# STM32U545 register map
File version: 1.0
CPU: CM33 r0p1, little endian, MPU, FPU, 4 interrupt priority bits
Registers are 32-bit, read-write, reset 0x0 unless marked. A register's access mark holds for its fields unless they carry their own. Offsets are from the block's base; [hi:lo] are bit positions; {n}, {i} and the like mark numbered series; 'fields as' and 'values as' point back to an identical list.

## OPAMP — Operational amplifiers
Base 0x46005000
Same registers: SEC_OPAMP 0x56005000
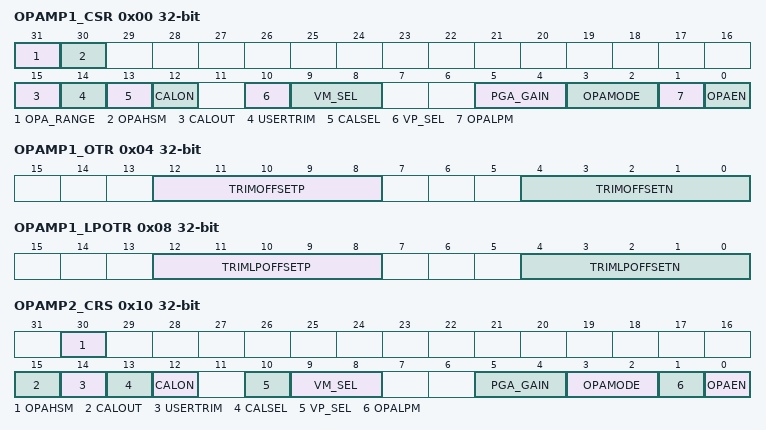
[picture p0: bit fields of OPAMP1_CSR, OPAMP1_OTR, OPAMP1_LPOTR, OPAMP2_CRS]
0x00 OPAMP1_CSR access per field — OPAMP1 control/status register
  [31] OPA_RANGE rw — OPAMP range setting This bit must be set before enabling the OPAMP and this bit affects all OPAMP instances.
  [30] OPAHSM rw — OPAMP high-speed mode This bit is effective for both normal and low-power modes.
  [15] CALOUT ro — OPAMP calibration output During the calibration mode, the offset is trimmed when this signal toggles.
  [14] USERTRIM rw — ‘factory’ or ‘user’ offset trimmed values selection This bit is active for normal and low-power modes.
  [13] CALSEL rw — Calibration selection
  [12] CALON rw — Calibration mode enable
  [10] VP_SEL rw — Non-inverted input selection
  [9:8] VM_SEL rw — Inverting input selection These bits are used only when OPAMODE = 00, 01 or 10. 1x: inverting input not externally connected
  [5:4] PGA_GAIN rw — OPAMP programmable amplifier gain value
  [3:2] OPAMODE rw — OPAMP PGA mode 00 and 01: internal PGA disabled
  [1] OPALPM rw — OPAMP low-power mode The OPAMP must be disabled to change this configuration.
  [0] OPAEN rw — OPAMP enable
0x04 OPAMP1_OTR (reset mask 0xFFFF0000) — OPAMP1 offset trimming register in normal mode
  [12:8] TRIMOFFSETP — Trim for PMOS differential pairs
  [4:0] TRIMOFFSETN — Trim for NMOS differential pairs
0x08 OPAMP1_LPOTR (reset mask 0xFFFF0000) — OPAMP1 offset trimming register in low-power mode
  [12:8] TRIMLPOFFSETP — Low-power mode trim for PMOS differential pairs
  [4:0] TRIMLPOFFSETN — Low-power mode trim for NMOS differential pairs
0x10 OPAMP2_CRS access per field — OPAMP2 control/status register
  [30] OPAHSM rw — OPAMP high-speed mode This bit is effective for both normal and high-speed modes.
  [15] CALOUT ro — OPAMP calibration output During calibration mode, the offset is trimmed when this signal toggles.
  [14] USERTRIM rw — ‘factory’ or ‘user’ offset trimmed values selection This bit is active for normal and low-power modes.
  [13] CALSEL rw — Calibration selection
  [12] CALON rw — Calibration mode enable
  [10] VP_SEL rw — Non inverted input selection
  [9:8] VM_SEL rw — Inverting input selection These bits are used only when OPAMODE = 00, 01 or 10. in PGA mode for filtering) 1x: inverting input not externally connected
  [5:4] PGA_GAIN rw — OPAMP programmable amplifier gain value
  [3:2] OPAMODE rw — OPAMP PGA mode 00 and 01: internal PGA disabled
  [1] OPALPM rw — OPAMP low-power mode The OPAMP must be disabled to change this configuration.
  [0] OPAEN rw — OPAMP enable
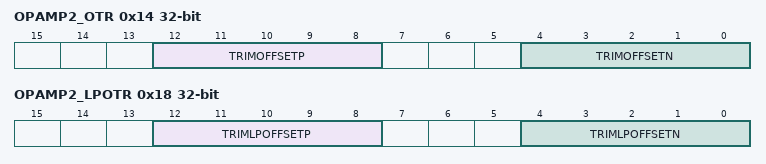
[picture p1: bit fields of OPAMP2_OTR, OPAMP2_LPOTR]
0x14 OPAMP2_OTR (reset mask 0xFFFF0000) — OPAMP2 offset trimming register in normal mode
  fields as OPAMP1_OTR
0x18 OPAMP2_LPOTR (reset mask 0xFFFF0000) — OPAMP2 offset trimming register in low-power mode
  fields as OPAMP1_LPOTR

## PKA — Private key accelerator
Base 0x420C2000
Same registers: SEC_PKA 0x520C2000
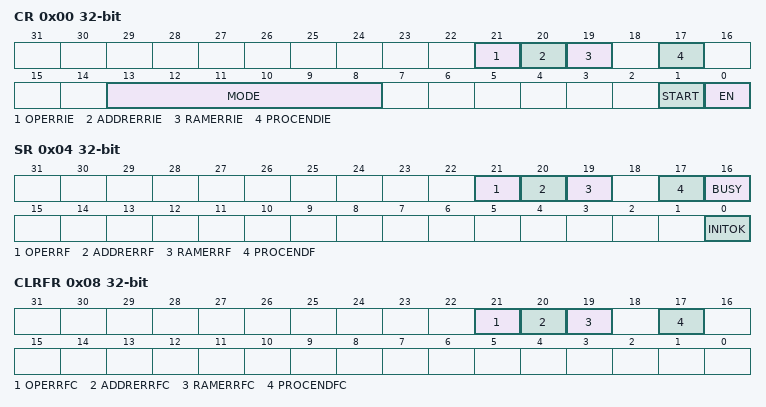
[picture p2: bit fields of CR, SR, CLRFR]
0x00 CR — Control register
  [21] OPERRIE — Operation error interrupt enable
  [20] ADDRERRIE — Address error interrupt enable
  [19] RAMERRIE — RAM error interrupt enable
  [17] PROCENDIE — End of operation interrupt enable
  [13:8] MODE — PKA Operation Mode
  [1] START — Start the operation
  [0] EN — Peripheral Enable
0x04 SR ro — PKA status register
  [21] OPERRF
  [20] ADDRERRF
  [19] RAMERRF
  [17] PROCENDF — PKA End of Operation flag
  [16] BUSY — PKA operation is in progress
  [0] INITOK
0x08 CLRFR wo — PKA clear flag register
  [21] OPERRFC
  [20] ADDRERRFC
  [19] RAMERRFC
  [17] PROCENDFC — Clear PKA End of Operation flag

## RAMCFG
Base 0x40026000
Same registers: SEC_RAMCFG 0x50026000
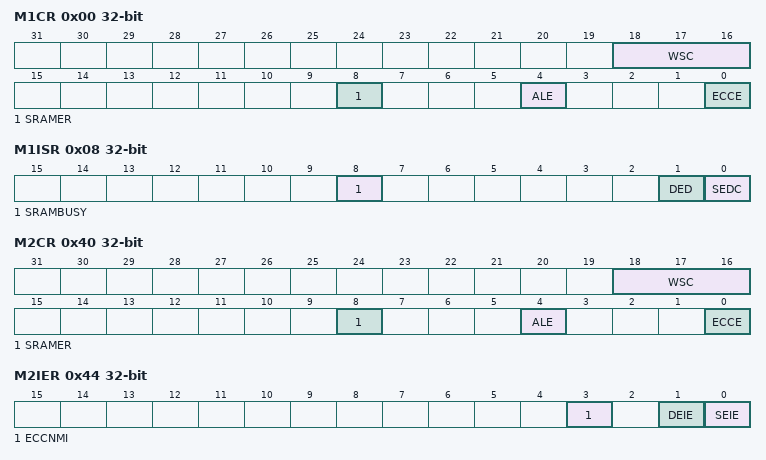
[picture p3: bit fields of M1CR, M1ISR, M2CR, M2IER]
0x00 M1CR — RAMCFG SRAM x control register
  [18:16] WSC, [8] SRAMER, [4] ALE, [0] ECCE
0x08 M1ISR ro — RAMCFG RAMx interrupt status register
  [8] SRAMBUSY, [1] DED, [0] SEDC
0x28 RAM1ERKEYR wo — RAMCFG SRAM x erase key register
  [7:0] ERASEKEY
0x40 M2CR — RAMCFG SRAM x control register
  [18:16] WSC, [8] SRAMER, [4] ALE, [0] ECCE
0x44 M2IER — RAMCFG SRAM x interrupt enable register
  [3] ECCNMI, [1] DEIE, [0] SEIE
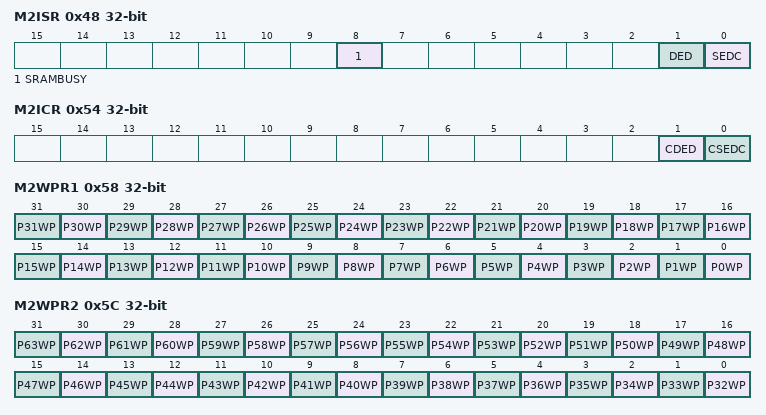
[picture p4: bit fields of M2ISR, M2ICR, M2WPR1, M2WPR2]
0x48 M2ISR ro — RAMCFG RAMx interrupt status register
  [8] SRAMBUSY, [1] DED, [0] SEDC
0x4C M2SEAR ro — RAMCFG RAM x ECC single error address register
  [31:0] ESEA
0x50 M2DEAR ro — RAMCFG RAM x ECC double error address register
  [31:0] EDEA
0x54 M2ICR — RAMCFG RAM x interrupt clear register x
  [1] CDED, [0] CSEDC
0x58 M2WPR1 — RAMCFG SRAM2 write protection register 1
  [n] P{n}WP (n=0..31)
0x5C M2WPR2 — RAMCFG SRAM2 write protection register 2
  [n-32] P{n}WP (n=32..63)
0x64 M2ECCKEYR wo — RAMCFG SRAM x ECC key register
  [7:0] ECCKEY
0x68 M2ERKEYR wo — RAMCFG SRAM x erase key register
  [7:0] ERASEKEY
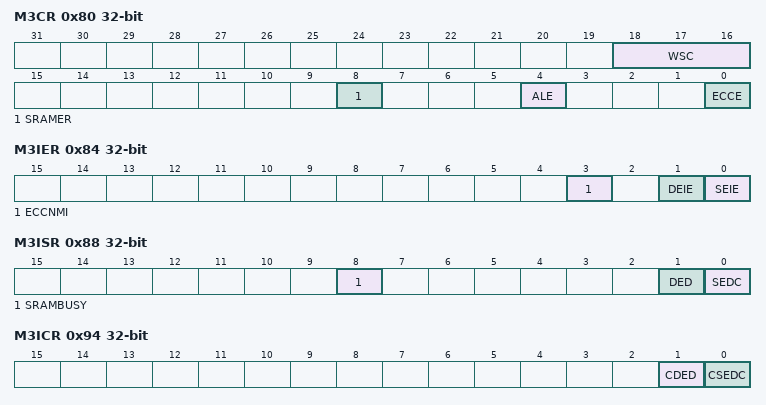
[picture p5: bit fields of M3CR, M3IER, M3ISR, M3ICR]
0x80 M3CR — RAMCFG SRAM x control register
  [18:16] WSC, [8] SRAMER, [4] ALE, [0] ECCE
0x84 M3IER — RAMCFG SRAM x interrupt enable register
  [3] ECCNMI, [1] DEIE, [0] SEIE
0x88 M3ISR ro — RAMCFG RAMx interrupt status register
  [8] SRAMBUSY, [1] DED, [0] SEDC
0x8C M3SEAR ro — RAMCFG RAM x ECC single error address register
  [31:0] ESEA
0x90 M3DEAR ro — RAMCFG RAM x ECC double error address register
  [31:0] EDEA
0x94 M3ICR — RAMCFG RAM x interrupt clear register x
  [1] CDED, [0] CSEDC
0xA4 M3ECCKEYR wo — RAMCFG SRAM x ECC key register
  [7:0] ECCKEY
0xA8 M3ERKEYR wo — RAMCFG SRAM x erase key register
  [7:0] ERASEKEY
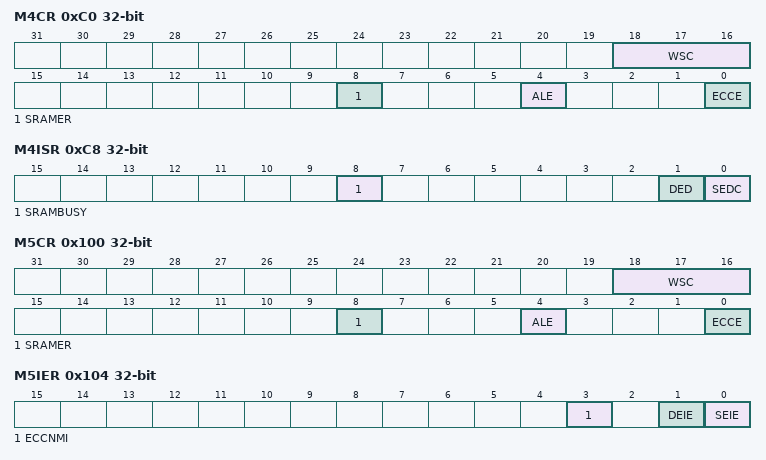
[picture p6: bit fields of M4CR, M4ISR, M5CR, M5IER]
0xC0 M4CR — RAMCFG SRAM x control register
  [18:16] WSC, [8] SRAMER, [4] ALE, [0] ECCE
0xC8 M4ISR ro — RAMCFG RAMx interrupt status register
  [8] SRAMBUSY, [1] DED, [0] SEDC
0xE8 M4ERKEYR wo — RAMCFG SRAM x erase key register
  [7:0] ERASEKEY
0x100 M5CR — RAMCFG SRAM x control register
  [18:16] WSC, [8] SRAMER, [4] ALE, [0] ECCE
0x104 M5IER — RAMCFG SRAM x interrupt enable register
  [3] ECCNMI, [1] DEIE, [0] SEIE
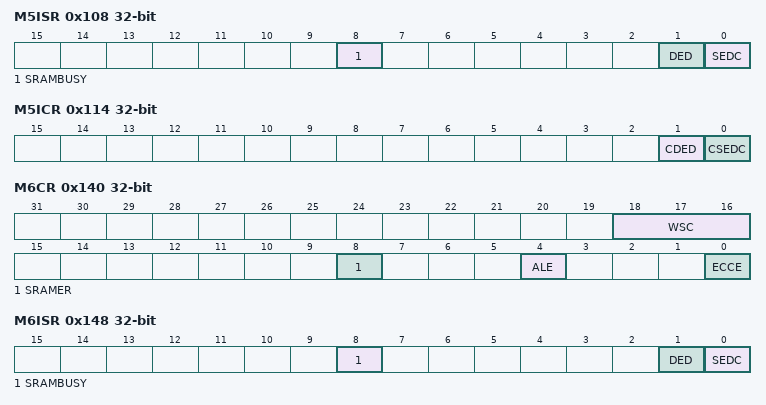
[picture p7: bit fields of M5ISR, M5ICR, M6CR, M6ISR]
0x108 M5ISR ro — RAMCFG RAMx interrupt status register
  [8] SRAMBUSY, [1] DED, [0] SEDC
0x10C M5SEAR ro — RAMCFG RAM x ECC single error address register
  [31:0] ESEA
0x110 M5DEAR ro — RAMCFG RAM x ECC double error address register
  [31:0] EDEA
0x114 M5ICR — RAMCFG RAM x interrupt clear register x
  [1] CDED, [0] CSEDC
0x124 M5ECCKEYR — RAMCFG RAM x interrupt clear register x
  [7:0] ECCKEY
0x128 M5ERKEYR
  [7:0] ERASEKEY wo — Erase write protection key The following steps are required to unlock the write protection of the SRAMER bit in the RAMCFG_MxCR register. 1) Write 0xCA into ERASEKEY[7:0]. 2) Write 0x53 into ERASEKEY[7:0]. Note: Writing a wrong key reactivates the write protection.
0x140 M6CR — memory x control register
  [18:16] WSC, [8] SRAMER, [4] ALE, [0] ECCE
0x148 M6ISR ro
  [8] SRAMBUSY — SRAM busy with erase operation Note: Depending on the SRAM, the erase operation can be performed due to software request, system reset if the option bit is enabled, tamper detection or readout protection regression. Refer to .
  [1] DED — ECC double error detected Note: This bit is reserved and must be kept at reset value in SRAM1, SRAM4 and SRAM5 interrupt status registers.
  [0] SEDC — ECC single error detected and corrected Note: This bit is reserved and must be kept at reset value in SRAM1, SRAM4 and SRAM5 interrupt status registers.
0x168 M6ERKEYR
  fields as M5ERKEYR
